# MKE14F16 register map
Vendor: Freescale Semiconductor, Inc.; Series: Kinetis_E; File version: 1.6
CPU: CM4 r0p1, little endian, no MPU, FPU, VTOR, 4 interrupt priority bits
Registers are 32-bit, read-write, reset 0x0 unless marked. A register's access mark holds for its fields unless they carry their own. Offsets are from the block's base; [hi:lo] are bit positions; {n}, {i} and the like mark numbered series; 'fields as' and 'values as' point back to an identical list.

## TRGMUX1 — TRGMUX
Base 0x40063000
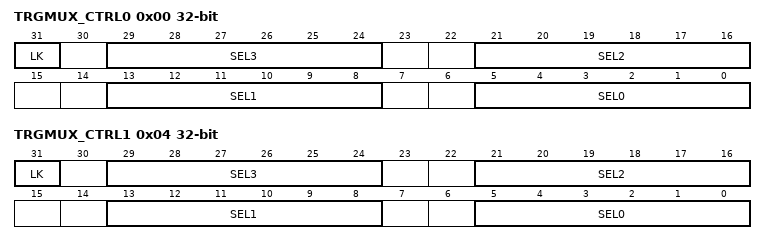
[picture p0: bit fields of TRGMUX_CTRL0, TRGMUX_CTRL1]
0x00 TRGMUX_CTRL0 — TRGMUX Register
  [31] LK ro — Enable
    0=Register can be written; 1=Register cannot be written until the next system Reset
  [8n+5:8n] SEL{n} (n=0..3) — Trigger MUX Input {n} Source Select
0x04 TRGMUX_CTRL1 — TRGMUX Register
  fields as TRGMUX_CTRL0

## PMC
Base 0x4007D000; register names take the prefix PMC_
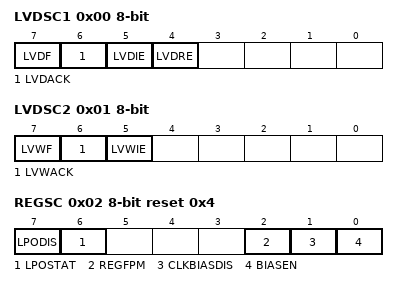
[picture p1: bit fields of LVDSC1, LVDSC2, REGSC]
0x00 LVDSC1 8-bit — Low Voltage Detect Status and Control 1 Register
  [7] LVDF ro — Low Voltage Detect Flag
    0=Low-voltage event not detected; 1=Low-voltage event detected
  [6] LVDACK wo — Low Voltage Detect Acknowledge
  [5] LVDIE — Low Voltage Detect Interrupt Enable
    0=Hardware interrupt disabled (use polling); 1=Request a hardware interrupt when LVDF = 1
  [4] LVDRE — Low Voltage Detect Reset Enable
    0=No system resets on low voltage detect events; 1=If the supply voltage falls below VLVD, a system reset will be generated
0x01 LVDSC2 8-bit — Low Voltage Detect Status and Control 2 Register
  [7] LVWF ro — Low-Voltage Warning Flag
    0=Low-voltage warning event not detected; 1=Low-voltage warning event detected
  [6] LVWACK wo — Low-Voltage Warning Acknowledge
  [5] LVWIE — Low-Voltage Warning Interrupt Enable
    0=Hardware interrupt disabled (use polling); 1=Request a hardware interrupt when LVWF=1
0x02 REGSC 8-bit reset 0x4 — Regulator Status and Control Register
  [7] LPODIS — LPO Disable Bit
    0=Low power oscillator enabled; 1=Low power oscillator disabled
  [6] LPOSTAT ro — LPO Status Bit
    0=Low power oscillator in low phase; 1=Low power oscillator in high phase
  [2] REGFPM ro — Regulator in Full Performance Mode Status Bit
    0=Regulator is in low power mode or transition to/from; 1=Regulator is in full performance mode
  [1] CLKBIASDIS — Clock Bias Disable Bit
    0=No effect; 1=In STOP or VLPS mode the bias currents and reference voltages for the following clock modules are disabled: SIRC, FIRC, PLL. (if available on device)
  [0] BIASEN — Bias Enable Bit
    0=Biasing disabled, core logic can run in full performance; 1=Biasing enabled, core logic is slower and there are restrictions in allowed system clock speed (see device level specification for details)
0x04 LPOTRIM 8-bit — Low Power Oscillator Trim Register
  [4:0] LPOTRIM — LPO trimming bits

## SMC — System Mode Controller
Base 0x4007E000; register names take the prefix SMC_
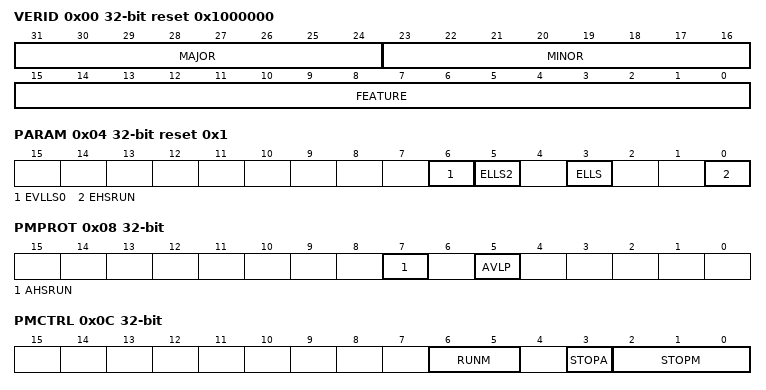
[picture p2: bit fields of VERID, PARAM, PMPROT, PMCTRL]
0x00 VERID ro reset 0x1000000 — SMC Version ID Register
  [31:24] MAJOR — Major Version Number
  [23:16] MINOR — Minor Version Number
  [15:0] FEATURE — Feature Specification Number
    0=Standard features implemented
0x04 PARAM ro reset 0x1 — SMC Parameter Register
  [6] EVLLS0 — Enable VLLS0 (if this mode exists on the SOC)
  [5] ELLS2 — Enable LLS2 (if this mode exists on the SOC)
  [3] ELLS — Enable LLS (if this mode exists on the SOC)
  [0] EHSRUN — Enable HSRUN
0x08 PMPROT — Power Mode Protection register
  [7] AHSRUN — Allow High Speed Run mode
    0=HSRUN is not allowed; 1=HSRUN is allowed
  [5] AVLP — Allow Very-Low-Power Modes
    0=VLPR, VLPW, and VLPS are not allowed; 1=VLPR, VLPW, and VLPS are allowed
0x0C PMCTRL — Power Mode Control register
  [6:5] RUNM — Run Mode Control
    0=Normal Run mode (RUN); 2=Very-Low-Power Run mode (VLPR); 3=High Speed Run mode (HSRUN)
  [3] STOPA ro — Stop Aborted
    0=The previous stop mode entry was successful; 1=The previous stop mode entry was aborted
  [2:0] STOPM — Stop Mode Control
    0=Normal Stop (STOP); 2=Very-Low-Power Stop (VLPS); 6=Reseved
0x10 STOPCTRL reset 0x3 — Stop Control Register
  [7:6] PSTOPO — Partial Stop Option
    0=STOP - Normal Stop mode; 1=PSTOP1 - Partial Stop with both system and bus clocks disabled; 2=PSTOP2 - Partial Stop with system clock disabled and bus clock enabled
0x14 PMSTAT ro reset 0x1 — Power Mode Status register
  [7:0] PMSTAT — Power Mode Status
